AUTOSAR XML (schema 00044)
package /ComponentTypes
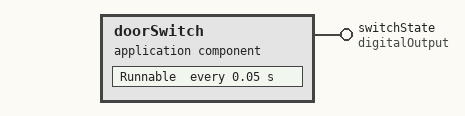
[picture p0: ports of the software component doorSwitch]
  application sw component type doorSwitch
    provide port switchState: nonqueued-sender-com-spec=outputStatus, provided-interface=digitalOutput
    behavior doorSwitch_InternalBehavior: supports-multiple-instantiation=true
      timing event TMT_Runnable: start-on-event=Runnable, period=0.05
      runnable Runnable
  swc implementation doorSwitch_Implementation: behavior=doorSwitch_InternalBehavior
